# ADC0 register map
Vendor: Texas Instruments
Peripheral module from a debugger description file (folder am243x).
Registers are 32-bit, read-write, reset 0x0 unless marked. A register's access mark holds for its fields unless they carry their own. Offsets are as the file gives them; lines under a group give offsets from that group; [hi:lo] are bit positions; {n}, {i} and the like mark numbered series; 'fields as' and 'values as' point back to an identical list; <NAME> marks a mode.

## ADC0
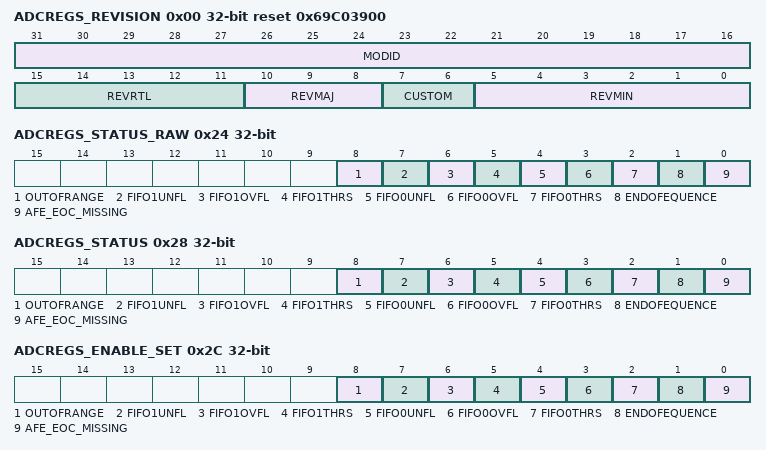
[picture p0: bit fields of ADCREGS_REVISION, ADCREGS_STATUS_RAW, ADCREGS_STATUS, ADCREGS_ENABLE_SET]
0x00 ADCREGS_REVISION ro reset 0x69C03900 — IP Revision Identifier (X.Y.R) Used by software to track features, bugs, and compatibility
  [31:16] MODID — Module ID field
  [15:11] REVRTL — RTL revision. Will vary depending on release.
  [10:8] REVMAJ — Major revision
  [7:6] CUSTOM
  [5:0] REVMIN — Minor revision
0x20 ADCREGS_EOI wo — The End of Interrupt (EOI) MISC Register allows the CPU to acknowledge completion of an interrupt by writing to the EOI for MISC interrupt sources. An eoi_write signal will be generated and another interrupt will be triggered if interrupt sources remain. This register will be reset one cycle after it has been written to.
  [0] LINENUMEOI — Write 0 to flag End Of Interrupt.
0x24 ADCREGS_STATUS_RAW access not given — The IRQ_STATUS_RAW register allows the adc12 interrupt sources to be manually set when writing a 1 to a specific bit. Write 0: No action Write 1: Set event Read 0: No event pending Read 1: Event pending
  [8] OUTOFRANGE — sample out of range (access R/W1TS)
  [7] FIFO1UNFL — fifo under flow (access R/W1TS)
  [6] FIFO1OVFL — fifo over flow (access R/W1TS)
  [5] FIFO1THRS — fifo thresholds met (access R/W1TS)
  [4] FIFO0UNFL — fifo under flow (access R/W1TS)
  [3] FIFO0OVFL — fifo over flow (access R/W1TS)
  [2] FIFO0THRS — fifo thresholds met (access R/W1TS)
  [1] ENDOFEQUENCE — end of sequence (access R/W1TS)
  [0] AFE_EOC_MISSING — eoc from the analog front end missing at expected time after soc (access R/W1TS)
0x28 ADCREGS_STATUS access not given — The IRQ_STATUS register allows the adc12 interrupt sources to be manually cleared when writing a 1 to a specific bit. Write 0: No action Write 1: Clear event Read 0: No event pending Read 1: Event pending
  [8] OUTOFRANGE — sample out of range (access R/W1TC)
  [7] FIFO1UNFL — fifo under flow (access R/W1TC)
  [6] FIFO1OVFL — fifo over flow (access R/W1TC)
  [5] FIFO1THRS — fifo thresholds met (access R/W1TC)
  [4] FIFO0UNFL — fifo under flow (access R/W1TC)
  [3] FIFO0OVFL — fifo over flow (access R/W1TC)
  [2] FIFO0THRS — fifo thresholds met (access R/W1TC)
  [1] ENDOFEQUENCE — end of sequence (access R/W1TC)
  [0] AFE_EOC_MISSING — eoc from the analog front end missing at expected time after soc (access R/W1TC)
0x2C ADCREGS_ENABLE_SET access not given — The IRQ_ENABLE_SET register allows the adc12 interrupt sources to be manually enabled when writing a 1 to a specific bit. Write 0: No action Write 1: Enable event Read 0: Event is disabled Read 1: Event is enabled
  fields as ADCREGS_STATUS_RAW
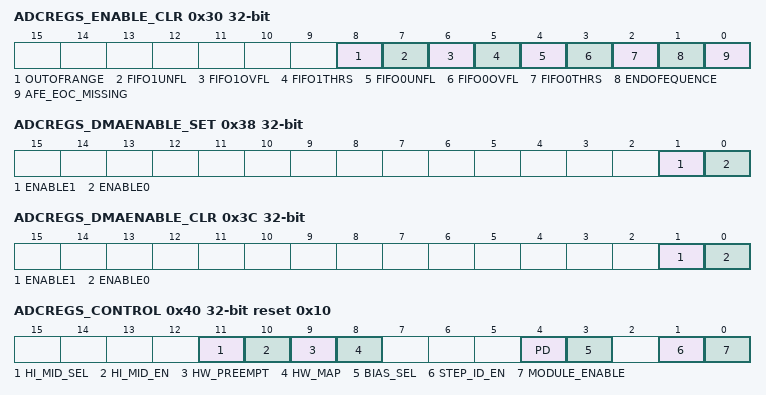
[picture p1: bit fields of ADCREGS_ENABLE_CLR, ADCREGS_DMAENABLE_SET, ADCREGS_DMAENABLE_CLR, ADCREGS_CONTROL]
0x30 ADCREGS_ENABLE_CLR access not given — The IRQ_ENABLE_CLR register allows the adc12 interrupt sources to be manually disabled when writing a 1 to a specific bit. Write 0: No action Write 1: Disable event Read 0: Event is disabled Read 1: Event is enabled
  fields as ADCREGS_STATUS
0x38 ADCREGS_DMAENABLE_SET access not given — The DMAENABLE_SET register allows the enabling of DMA requests
  [1] ENABLE1 — enable DMA reguest FIFO1 (access R/W1TS)
  [0] ENABLE0 — enable DMA reguest FIFO0 (access R/W1TS)
0x3C ADCREGS_DMAENABLE_CLR access not given — The DMAENABLE_CLR register allows the disabling of DMA requests
  [1] ENABLE1 — clears the enable of the DMA reguest FIFO1. Disables DMA request when writing 1 (access R/W1TC)
  [0] ENABLE0 — clears the enable of the DMA reguest FIFO0. Disables DMA request when writing 1 (access R/W1TC)
0x40 ADCREGS_CONTROL reset 0x10 — Controls various parameters of the cotroller state.
  [11] HI_MID_SEL — Functional safety debug mode. =1 choose ADCREFP, =0 VMID reference input to ADC
  [10] HI_MID_EN — Functional safety debug mode. enable fixed reference to ADC for testing
  [9] HW_PREEMPT — 1 steps are preempted
  [8] HW_MAP — 1 = hw events enabled
  [4] PD — AFE powered down
  [3] BIAS_SEL — AFE select bias control
  [1] STEP_ID_EN — writing 1 will store the stepid number with the captured adc data in the fifo
  [0] MODULE_ENABLE — ADC12_SS module enable bit. After programming all the configuration and step enable registers, write a 1 to this bit to start conversion. Writing a 0 will disable the module after the current conversion. Before turning on again, the ADC_SEQUENCER_STATUS register show read back STEP_ID=Idle and FSM_BUSY=0. Enabling the controller will be held off until mem_init_done =1.
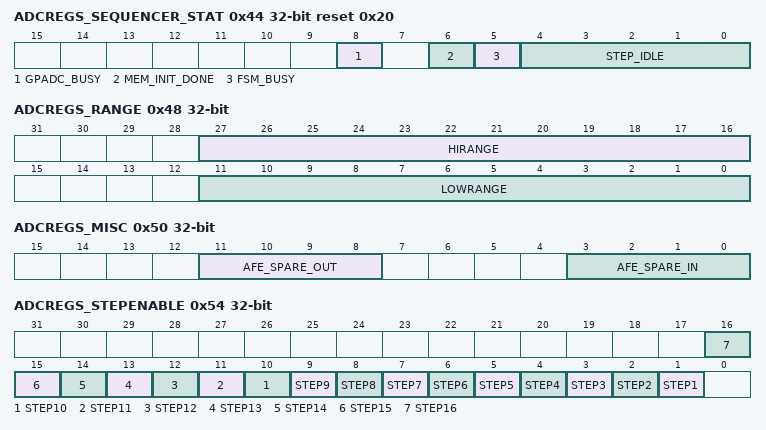
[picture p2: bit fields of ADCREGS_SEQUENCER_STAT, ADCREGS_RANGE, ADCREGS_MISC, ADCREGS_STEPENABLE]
0x44 ADCREGS_SEQUENCER_STAT ro reset 0x20 — SW can read this register to find out the currently scheduled step id being converted on the ADC port. If you want to turn the controller off and then back on, the step_id bit should be checked and compared to IDLE before enabling the ADC12_SS module again. Also, before enabling the controller again, the user should wait for the FSM bit 5 to read idl.
  [8] GPADC_BUSY — Monitor the AFE internal calibration, busy bit
  [6] MEM_INIT_DONE — status of ram initialization, 1= ram initialization to 0 after reset is done.
  [5] FSM_BUSY — status of fsm, 1= conversion in progress
  [4:0] STEP_IDLE — 10000 = idle, 000000 -> 01111 corresponds to step 1 -> step 16
0x48 ADCREGS_RANGE — This feature requires the range check interrupt bit to be enabled first. The user can decide which channel input is compared by programming the RangeCheck bit of the StepConfig Registers. It is up to software to sort through FIFO data to determine which channel data was out of range. Software should only use LSB 10 bits for comparison and make sure bits 11,12 are 0.
  [27:16] HIRANGE — If the sampled data is > value, then interrupt is generated
  [11:0] LOWRANGE — If the sampled data is < value, then interrupt is generated
0x50 ADCREGS_MISC access per field — Spare inputs of the AFE are driven by this register, spare outputs from the AFE are read.
  [11:8] AFE_SPARE_OUT ro — Spare outputs from AFE
  [3:0] AFE_SPARE_IN rw — Spare inputs to AFE
0x54 ADCREGS_STEPENABLE — Contains the enable bit for each step in the sequencer. When all steps are disabled, the FSM will stay in IDLE state. These bits can be enabled or disabled dynamically during operation. When a write to this register occurs during operational mode, the HW will make sure the new settings are updated after the END_OF_SEQUENCE event
  [n] STEP{n} (n=1..16) — Enable step
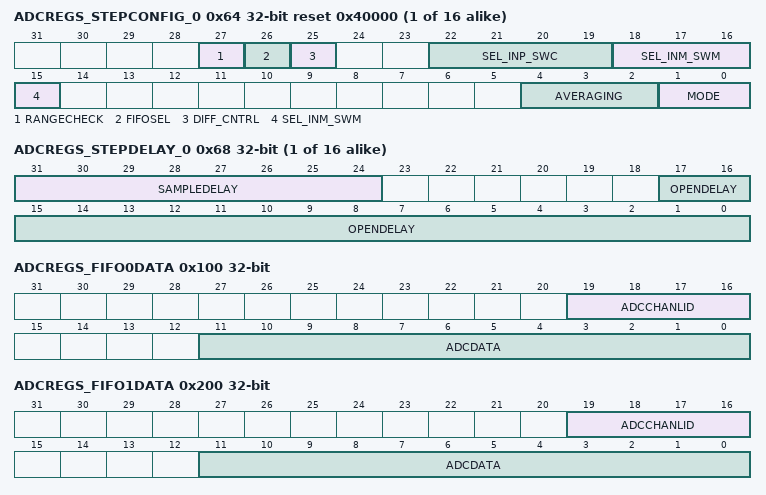
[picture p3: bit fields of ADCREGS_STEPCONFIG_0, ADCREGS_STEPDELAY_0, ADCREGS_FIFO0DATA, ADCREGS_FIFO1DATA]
{0x64+8i} ADCREGS_STEPCONFIG_{i} reset 0x40000 (i=0..15) — The user should write to this register the values of the input pins send to the AFE during step 1. the StepConfig WriteEnable bit should be set to 1 before a write can occur.
  [27] RANGECHECK — 0 = no range sel 1 = compare ADC data with range
  [26] FIFOSEL — Sampled data will be stored in FIFO0 when = 0, FIFO1 when = 1
  [25] DIFF_CNTRL — Differential control. Single ended when = 0, differential input when = 1
  [22:19] SEL_INP_SWC — SEL_INP pins SW configuration
  [18:15] SEL_INM_SWM — SEL_INM pins, negative differential
  [4:2] AVERAGING — 000 -> no average 001 -> 2 samples average 010 -> 4 samples average 011 -> 8 samples average 100 -> 16 samples average
  [1:0] MODE — 00 SW enabled one shot 01 SW enabled continuous 10 HW synchronized one-shot 11 HW synchronized continuous
{0x68+8i} ADCREGS_STEPDELAY_{i} (i=0..15) — Controls number of clock periods to sample and delay
  [31:24] SAMPLEDELAY — number of ADC clock cycles to sample. Any value programmed here will be added to the minimum requirement of 1 clock cycle.
  [17:0] OPENDELAY — Program the number of ADC clock cycles to wait after applying the step configuration registers and before sending the start of ADC conversion
0xE4 ADCREGS_FIFO0WC ro — FIFO word count status
  [8:0] NUMWDS — number of words in the FIFO
0xE8 ADCREGS_FIFO0THRESHOLD — FIFO threshold
  [7:0] THRESHOLD — Program the desired FIFO0 data sample level minus 1 to reach before generating interrupt to CPU
0xEC ADCREGS_FIFO0DMAREQ — dma request.
  [7:0] DMAREQLEVEL — Number of words minus 1 in FIFO0 before generating a DMA request
0xF0 ADCREGS_FIFO1WC ro — FIFO word count status
  [8:0] NUMWDS — number of words in the FIFO
0xF4 ADCREGS_FIFO1THRESHOLD — FIFO threshold
  [7:0] THRESHOLD — Program the desired FIFO1 data sample level minus 1 to reach before generating interrupt to CPU
0xF8 ADCREGS_FIFO1DMAREQ — dma request.
  [7:0] DMAREQLEVEL — Number of words minus 1 in FIFO1 before generating a DMA request
0x100 ADCREGS_FIFO0DATA ro — A read from this register will auto increment the FIFO read pointer. If you read when FIFO is empty,it will trigger an underflow interrupt
  [19:16] ADCCHANLID — Optional ID tag of channel that captured the data. If tag option is disabled, these bits will be 0
  [11:0] ADCDATA — sampled ADC converted data value stored in FIFO
0x200 ADCREGS_FIFO1DATA ro — A read from this register will auto increment the FIFO read pointer. If you read when FIFO is empty,it will trigger an underflow interrupt
  fields as ADCREGS_FIFO0DATA
